# MSP430FR5739 register map
File version: 1.1
CPU: msp430
Registers are 16-bit, access not given, reset 0x0 unless marked. A register's access mark holds for its fields unless they carry their own. Offsets are from the block's base; [hi:lo] are bit positions; {n}, {i} and the like mark numbered series.

## USCI_A0__UART_Mode
Base 0x00000000
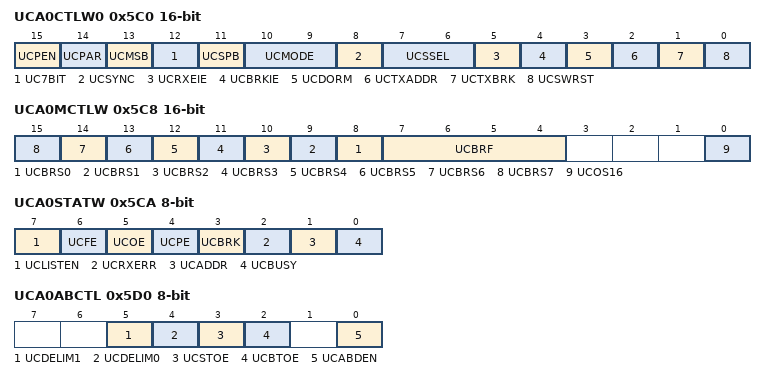
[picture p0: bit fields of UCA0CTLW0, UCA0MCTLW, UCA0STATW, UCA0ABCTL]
0x5C0 UCA0CTLW0 — USCI A0 Control Word Register 0
  [15] UCPEN — [15:15] Async. Mode: Parity enable
  [14] UCPAR — [14:14] Async. Mode: Parity 0:odd / 1:even
  [13] UCMSB — [13:13] Async. Mode: MSB first 0:LSB / 1:MSB
  [12] UC7BIT — [12:12] Async. Mode: Data Bits 0:8-bits / 1:7-bits
  [11] UCSPB — [11:11] Async. Mode: Stop Bits 0:one / 1: two
  [10:9] UCMODE — [10:9] Async. Mode: USCI Mode 1
    {v}=Sync. Mode: USCI Mode: {v} (v=0..3)
  [8] UCSYNC — [8:8] Sync-Mode 0:UART-Mode / 1:SPI-Mode
  [7:6] UCSSEL — [7:6] USCI 0 Clock Source Select 1
    {v}=USCI 0 Clock Source: {v} (v=0..3)
  [5] UCRXEIE — [5:5] RX Error interrupt enable
  [4] UCBRKIE — [4:4] Break interrupt enable
  [3] UCDORM — [3:3] Dormant (Sleep) Mode
  [2] UCTXADDR — [2:2] Send next Data as Address
  [1] UCTXBRK — [1:1] Send next Data as Break
  [0] UCSWRST — [0:0] USCI Software Reset
0x5C0 UCA0CTL1 8-bit — USCI A0 Control Register 1
0x5C1 UCA0CTL0 8-bit — USCI A0 Control Register 0
0x5C2 UCA0CTLW1 — USCI A0 Control Word Register 1
  [1:0] UCGLIT — [1:0] USCI Deglitch Time Bit 1
    {v}=USCI Deglitch time: {v} (v=0..3)
0x5C6 UCA0BRW — USCI A0 Baud Word Rate 0
0x5C6 UCA0BR0 8-bit — USCI A0 Baud Rate 0
0x5C7 UCA0BR1 8-bit — USCI A0 Baud Rate 1
0x5C8 UCA0MCTLW — USCI A0 Modulation Control
  [n+8] UCBRS{n} (n=0..7) — [{n+8}:{n+8}] USCI Second Stage Modulation Select {n}
  [7:4] UCBRF — [7:4] USCI First Stage Modulation Select 3
    {v}=USCI First Stage Modulation: {v} (v=0..9); 10=USCI First Stage Modulation: A; 11=USCI First Stage Modulation: B; 12=USCI First Stage Modulation: C; 13=USCI First Stage Modulation: D; 14=USCI First Stage Modulation: E; 15=USCI First Stage Modulation: F
  [0] UCOS16 — [0:0] USCI 16-times Oversampling enable
0x5CA UCA0STATW 8-bit — USCI A0 Status Register
  [7] UCLISTEN — [7:7] USCI Listen mode
  [6] UCFE — [6:6] USCI Frame Error Flag
  [5] UCOE — [5:5] USCI Overrun Error Flag
  [4] UCPE — [4:4] USCI Parity Error Flag
  [3] UCBRK — [3:3] USCI Break received
  [2] UCRXERR — [2:2] USCI RX Error Flag
  [1] UCADDR — [1:1] USCI Address received Flag
  [0] UCBUSY — [0:0] USCI Busy Flag
0x5CC UCA0RXBUF — USCI A0 Receive Buffer
0x5CE UCA0TXBUF — USCI A0 Transmit Buffer
0x5D0 UCA0ABCTL 8-bit — USCI A0 LIN Control
  [5] UCDELIM1 — [5:5] Break Sync Delimiter 1
  [4] UCDELIM0 — [4:4] Break Sync Delimiter 0
  [3] UCSTOE — [3:3] Sync-Field Timeout error
  [2] UCBTOE — [2:2] Break Timeout error
  [0] UCABDEN — [0:0] Auto Baud Rate detect enable
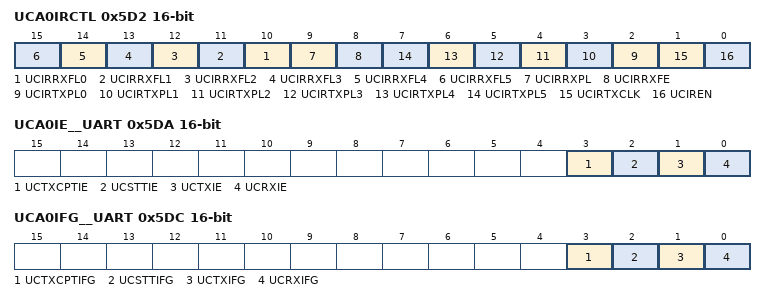
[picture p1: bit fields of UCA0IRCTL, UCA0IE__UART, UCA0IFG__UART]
0x5D2 UCA0IRCTL — USCI A0 IrDA Transmit Control
  [n+10] UCIRRXFL{n} (n=0..5) — [{n+10}:{n+10}] IRDA Receive Filter Length {n}
  [9] UCIRRXPL — [9:9] IRDA Receive Input Polarity
  [8] UCIRRXFE — [8:8] IRDA Receive Filter enable
  [n+2] UCIRTXPL{n} (n=0..5) — [{n+2}:{n+2}] IRDA Transmit Pulse Length {n}
  [1] UCIRTXCLK — [1:1] IRDA Transmit Pulse Clock Select
  [0] UCIREN — [0:0] IRDA Encoder/Decoder enable
0x5D2 UCA0IRTCTL 8-bit — USCI A0 IrDA Transmit Control
0x5D3 UCA0IRRCTL 8-bit — USCI A0 IrDA Receive Control
0x5DA UCA0IE — USCI A0 Interrupt Enable Register
0x5DA UCA0IE__UART — USCI A0 Interrupt Enable Register
  [3] UCTXCPTIE — [3:3] UART Transmit Complete Interrupt Enable
  [2] UCSTTIE — [2:2] UART Start Bit Interrupt Enalble
  [1] UCTXIE — [1:1] UART Transmit Interrupt Enable
  [0] UCRXIE — [0:0] UART Receive Interrupt Enable
0x5DC UCA0IFG — USCI A0 Interrupt Flags Register
0x5DC UCA0IFG__UART — USCI A0 Interrupt Flags Register
  [3] UCTXCPTIFG — [3:3] UART Transmit Complete Interrupt Flag
  [2] UCSTTIFG — [2:2] UART Start Bit Interrupt Flag
  [1] UCTXIFG — [1:1] UART Transmit Interrupt Flag
  [0] UCRXIFG — [0:0] UART Receive Interrupt Flag
0x5DE UCA0IV — USCI A0 Interrupt Vector Register
